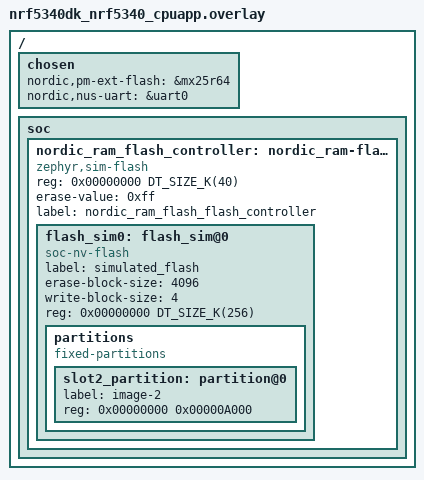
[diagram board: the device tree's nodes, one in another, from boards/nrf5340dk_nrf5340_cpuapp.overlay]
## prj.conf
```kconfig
#
# Copyright (c) 2018 Nordic Semiconductor
#
# SPDX-License-Identifier: LicenseRef-Nordic-5-Clause
#

# Enable the UART driver
CONFIG_UART_ASYNC_API=y
CONFIG_NRFX_UARTE0=y
CONFIG_SERIAL=y

CONFIG_GPIO=y

# Make sure printk is printing to the UART console
CONFIG_CONSOLE=y
CONFIG_UART_CONSOLE=y

CONFIG_HEAP_MEM_POOL_SIZE=2048

CONFIG_BT=y
CONFIG_BT_PERIPHERAL=y
CONFIG_BT_DEVICE_NAME="Pigrun_UART_Service"
CONFIG_BT_DEVICE_APPEARANCE=833
CONFIG_BT_MAX_CONN=1
CONFIG_BT_MAX_PAIRED=1

# Enable the NUS service
CONFIG_BT_NUS=y

# Enable bonding
CONFIG_BT_SETTINGS=y
CONFIG_FLASH=y
CONFIG_FLASH_PAGE_LAYOUT=y
CONFIG_FLASH_MAP=y
CONFIG_NVS=y
CONFIG_SETTINGS=y

# Enable DK LED and Buttons library
CONFIG_DK_LIBRARY=y

# This example requires more workqueue stack
CONFIG_SYSTEM_WORKQUEUE_STACK_SIZE=2048

# Config logger
CONFIG_LOG=y
CONFIG_USE_SEGGER_RTT=y
CONFIG_LOG_BACKEND_RTT=y
CONFIG_LOG_BACKEND_UART=n

CONFIG_ASSERT=y
```

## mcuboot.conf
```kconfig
CONFIG_MCUBOOT_UTIL_LOG_LEVEL_DBG=y
CONFIG_MCUBOOT_LOG_LEVEL_DBG=y
CONFIG_LOG_BACKEND_UART=y
CONFIG_MCUBOOT_SERIAL=y
CONFIG_BOOT_SERIAL_UART=y
CONFIG_BOOT_SERIAL_DETECT_PORT="GPIO_0" # or GPIO_1 if your pin is on that port
CONFIG_BOOT_SERIAL_DETECT_PIN=23
CONFIG_BOOT_SERIAL_DETECT_PIN_VAL=0
CONFIG_UART_CONSOLE=n
CONFIG_LOG=y
CONFIG_MCUBOOT_INDICATION_LED=y
```

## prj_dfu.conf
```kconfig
# Happirin add for DFU develop
CONFIG_CONSOLE=y
CONFIG_SERIAL=y
CONFIG_BOOTLOADER_MCUBOOT=y
CONFIG_MCUMGR=y
CONFIG_PCD_APP=y

# Increase system workqueue stack size to prevent stack overflows while handling
# SMP requests.
CONFIG_SYSTEM_WORKQUEUE_STACK_SIZE=4096
CONFIG_MAIN_STACK_SIZE=4096
CONFIG_THREAD_NAME=y
# BT dfu
# CONFIG_MCUMGR_LOG_LEVEL_DBG=y
# CONFIG_MCUMGR_CMD_OS_MGMT=y
# CONFIG_MCUMGR_CMD_IMG_MGMT=y
CONFIG_MCUMGR_SMP_BT=y
CONFIG_MCUMGR_SMP_BT_AUTHEN=n
# CONFIG_PCD_LOG_LEVEL_DBG=y
CONFIG_BT_L2CAP_TX_MTU=498
CONFIG_BT_BUF_ACL_TX_SIZE=251
CONFIG_BT_BUF_ACL_RX_SIZE=502
CONFIG_MCUMGR_BUF_COUNT=6

# Serial DFU
CONFIG_MCUMGR_SMP_UART=y
CONFIG_UART_MCUMGR_RX_BUF_SIZE=512
CONFIG_MCUMGR_BUF_SIZE=512
## Required by the `taskstat` command.
CONFIG_THREAD_MONITOR=y
CONFIG_STATS=y
CONFIG_STATS_NAMES=y
CONFIG_MCUMGR_CMD_OS_MGMT=y
CONFIG_MCUMGR_CMD_STAT_MGMT=y
CONFIG_MCUMGR_CMD_IMG_MGMT=y
```

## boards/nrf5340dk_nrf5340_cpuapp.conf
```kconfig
#
# Copyright (c) 2022 Nordic Semiconductor ASA
#
# SPDX-License-Identifier: LicenseRef-Nordic-5-Clause
#
################################################################################
# Application overlay - Nrf5340: DFU

CONFIG_MCUMGR=y
CONFIG_MCUMGR_SMP_BT=y
CONFIG_MCUMGR_SMP_BT_AUTHEN=n
CONFIG_MCUMGR_SMP_BT_CONN_PARAM_CONTROL=y

CONFIG_MCUMGR_CMD_IMG_MGMT=y
CONFIG_MCUMGR_CMD_OS_MGMT=y

# Enable custom SMP request to erase settings partition.
CONFIG_MCUMGR_GRP_ZEPHYR_BASIC=y
CONFIG_MCUMGR_GRP_BASIC_CMD_STORAGE_ERASE=y

# Increase system workqueue stack size to prevent stack overflows while handling
# SMP requests.
CONFIG_SYSTEM_WORKQUEUE_STACK_SIZE=2800

CONFIG_BT_L2CAP_TX_MTU=498
CONFIG_BT_BUF_ACL_TX_SIZE=251
CONFIG_BT_BUF_ACL_RX_SIZE=502

# Use connection parameters that ensure quick data transfer
CONFIG_BT_PERIPHERAL_PREF_MIN_INT=6
CONFIG_BT_PERIPHERAL_PREF_MAX_INT=6
CONFIG_BT_PERIPHERAL_PREF_LATENCY=99
CONFIG_BT_PERIPHERAL_PREF_TIMEOUT=400

################################################################################
# Bootloader configuration

CONFIG_BOOTLOADER_MCUBOOT=y
CONFIG_MCUBOOT_IMAGE_VERSION="1.0.0+0"
CONFIG_UPDATEABLE_IMAGE_NUMBER=2

CONFIG_IMG_MANAGER=y
CONFIG_MCUBOOT_IMG_MANAGER=y
CONFIG_IMG_ERASE_PROGRESSIVELY=y

################################################################################
# External flash configuration

CONFIG_NORDIC_QSPI_NOR=y
CONFIG_NORDIC_QSPI_NOR_FLASH_LAYOUT_PAGE_SIZE=4096
CONFIG_NORDIC_QSPI_NOR_STACK_WRITE_BUFFER_SIZE=16

# FLASH nop device is enabled to prevent bus faults when mcumgr tries to access
# simulated partition with network core image data.
CONFIG_FLASH_NOP_DEVICE=y
```

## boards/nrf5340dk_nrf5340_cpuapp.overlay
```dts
/*
 * Copyright (c) 2022 Nordic Semiconductor ASA
 *
 * SPDX-License-Identifier: LicenseRef-Nordic-5-Clause
 */

/ {
	chosen {
		nordic,pm-ext-flash = &mx25r64;
	};
};

/ {
	chosen {
		nordic,nus-uart = &uart0;
	};
};

/*
 * This section is used to enable a partition which is used through the flash API
 * but which is in reality stored in RAM. This is done to load data from
 * external flash to the network core. Since the network core cannot access
 * the external flash directly, the data is buffered in RAM before being
 * copied by the network core to the network core flash.
 *
 * The partition must be enabled by the application configuration to prevent
 * bus faults when mcumgr tries to access simulated partition with network core
 * image data.
 */

/ {
	soc {
		/* Add a flash controller which has the compatible
		 * 'zephyr,sim-flash'. This will ensure that the flash
		 * simulator can use it. None of the other properties in this
		 * node is used for anything.
		 */
		nordic_ram_flash_controller: nordic_ram-flash-controller@0 {
			compatible = "zephyr,sim-flash";
			reg = <0x00000000 DT_SIZE_K(40)>;
			#address-cells = <1>;
			#size-cells = <1>;
			erase-value = <0xff>;
			label = "nordic_ram_flash_flash_controller";

			/* This node label must match that used in the flash
			 * simulator.
			 */
			flash_sim0: flash_sim@0 {
				status = "okay";
				compatible = "soc-nv-flash";
				label = "simulated_flash";
				erase-block-size = <4096>;
				write-block-size = <4>;
				reg = <0x00000000 DT_SIZE_K(256)>;

				partitions {
					compatible = "fixed-partitions";
					#address-cells = <1>;
					#size-cells = <1>;

					/* This partition must be defined for
					 * MCUboot to find the partition ID
					 * of the primary slot for image 1,
					 * which is stored in this partition.
					 */
					slot2_partition: partition@0 {
						label = "image-2";
						reg = <0x00000000 0x00000A000>;
					};
				};
			};
		};
	};

};
```

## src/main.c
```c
/*
 * Copyright (c) 2018 Nordic Semiconductor ASA
 *
 * SPDX-License-Identifier: LicenseRef-Nordic-5-Clause
 */

/** @file
 *  @brief Nordic UART Bridge Service (NUS) sample
 */
#include "uart_async_adapter.h"

#include <zephyr/types.h>
#include <zephyr.h>
#include <drivers/uart.h>
#include <usb/usb_device.h>

#include <device.h>
#include <devicetree.h>
#include <soc.h>

#include <bluetooth/bluetooth.h>
#include <bluetooth/uuid.h>
#include <bluetooth/gatt.h>
#include <bluetooth/hci.h>

#include <bluetooth/services/nus.h>

#include <dk_buttons_and_leds.h>

#include <settings/settings.h>

#include <stdio.h>

#include <logging/log.h>

#define LOG_MODULE_NAME peripheral_uart
LOG_MODULE_REGISTER(LOG_MODULE_NAME);

#define STACKSIZE CONFIG_BT_NUS_THREAD_STACK_SIZE
#define PRIORITY 7

#define DEVICE_NAME CONFIG_BT_DEVICE_NAME
#define DEVICE_NAME_LEN	(sizeof(DEVICE_NAME) - 1)

#define RUN_STATUS_LED DK_LED1
#define RUN_LED_BLINK_INTERVAL 1000

#define CON_STATUS_LED DK_LED2

#define KEY_PASSKEY_ACCEPT DK_BTN1_MSK
#define KEY_PASSKEY_REJECT DK_BTN2_MSK

#define UART_BUF_SIZE CONFIG_BT_NUS_UART_BUFFER_SIZE
#define UART_WAIT_FOR_BUF_DELAY K_MSEC(50)
#define UART_WAIT_FOR_RX CONFIG_BT_NUS_UART_RX_WAIT_TIME

static K_SEM_DEFINE(ble_init_ok, 0, 1);

static struct bt_conn *current_conn;
static struct bt_conn *auth_conn;

static const struct device *uart = DEVICE_DT_GET(DT_CHOSEN(nordic_nus_uart));
static struct k_work_delayable uart_work;

struct uart_data_t {
	void *fifo_reserved;
	uint8_t data[UART_BUF_SIZE];
	uint16_t len;
};

static K_FIFO_DEFINE(fifo_uart_tx_data);
static K_FIFO_DEFINE(fifo_uart_rx_data);

static const struct bt_data ad[] = {
	BT_DATA_BYTES(BT_DATA_FLAGS, (BT_LE_AD_GENERAL | BT_LE_AD_NO_BREDR)),
	BT_DATA(BT_DATA_NAME_COMPLETE, DEVICE_NAME, DEVICE_NAME_LEN),
};

static const struct bt_data sd[] = {
	BT_DATA_BYTES(BT_DATA_UUID128_ALL, BT_UUID_NUS_VAL),
};

#if CONFIG_BT_NUS_UART_ASYNC_ADAPTER
UART_ASYNC_ADAPTER_INST_DEFINE(async_adapter);
#else
static const struct device *const async_adapter;
#endif

static void uart_cb(const struct device *dev, struct uart_event *evt, void *user_data)
{
	ARG_UNUSED(dev);

	static size_t aborted_len;
	struct uart_data_t *buf;
	static uint8_t *aborted_buf;
	static bool disable_req;

	switch (evt->type) {
	case UART_TX_DONE:
		LOG_DBG("UART_TX_DONE");
		if ((evt->data.tx.len == 0) ||
		    (!evt->data.tx.buf)) {
			return;
		}

		if (aborted_buf) {
			buf = CONTAINER_OF(aborted_buf, struct uart_data_t,
					   data);
			aborted_buf = NULL;
			aborted_len = 0;
		} else {
			buf = CONTAINER_OF(evt->data.tx.buf, struct uart_data_t,
					   data);
		}

		k_free(buf);

		buf = k_fifo_get(&fifo_uart_tx_data, K_NO_WAIT);
		if (!buf) {
			return;
		}

		if (uart_tx(uart, buf->data, buf->len, SYS_FOREVER_MS)) {
			LOG_WRN("Failed to send data over UART");
		}

		break;

	case UART_RX_RDY:
		LOG_DBG("UART_RX_RDY");
		buf = CONTAINER_OF(evt->data.rx.buf, struct uart_data_t, data);
		buf->len += evt->data.rx.len;

		if (disable_req) {
			return;
		}

		if ((evt->data.rx.buf[buf->len - 1] == '\n') ||
		    (evt->data.rx.buf[buf->len - 1] == '\r')) {
			disable_req = true;
			uart_rx_disable(uart);
		}

		break;

	case UART_RX_DISABLED:
		LOG_DBG("UART_RX_DISABLED");
		disable_req = false;

		buf = k_malloc(sizeof(*buf));
		if (buf) {
			buf->len = 0;
		} else {
			LOG_WRN("Not able to allocate UART receive buffer");
			k_work_reschedule(&uart_work, UART_WAIT_FOR_BUF_DELAY);
			return;
		}

		uart_rx_enable(uart, buf->data, sizeof(buf->data),
			       UART_WAIT_FOR_RX);

		break;

	case UART_RX_BUF_REQUEST:
		LOG_DBG("UART_RX_BUF_REQUEST");
		buf = k_malloc(sizeof(*buf));
		if (buf) {
			buf->len = 0;
			uart_rx_buf_rsp(uart, buf->data, sizeof(buf->data));
		} else {
			LOG_WRN("Not able to allocate UART receive buffer");
		}

		break;

	case UART_RX_BUF_RELEASED:
		LOG_DBG("UART_RX_BUF_RELEASED");
		buf = CONTAINER_OF(evt->data.rx_buf.buf, struct uart_data_t,
				   data);

		if (buf->len > 0) {
			k_fifo_put(&fifo_uart_rx_data, buf);
		} else {
			k_free(buf);
		}

		break;

	case UART_TX_ABORTED:
		LOG_DBG("UART_TX_ABORTED");
		if (!aborted_buf) {
			aborted_buf = (uint8_t *)evt->data.tx.buf;
		}

		aborted_len += evt->data.tx.len;
		buf = CONTAINER_OF(aborted_buf, struct uart_data_t,
				   data);

		uart_tx(uart, &buf->data[aborted_len],
			buf->len - aborted_len, SYS_FOREVER_MS);

		break;

	default:
		break;
	}
}

static void uart_work_handler(struct k_work *item)
{
	struct uart_data_t *buf;

	buf = k_malloc(sizeof(*buf));
	if (buf) {
		buf->len = 0;
	} else {
		LOG_WRN("Not able to allocate UART receive buffer");
		k_work_reschedule(&uart_work, UART_WAIT_FOR_BUF_DELAY);
		return;
	}

	uart_rx_enable(uart, buf->data, sizeof(buf->data), UART_WAIT_FOR_RX);
}

static bool uart_test_async_api(const struct device *dev)
{
	const struct uart_driver_api *api =
			(const struct uart_driver_api *)dev->api;

	return (api->callback_set != NULL);
}

static int uart_init(void)
{
	int err;
	int pos;
	struct uart_data_t *rx;
	struct uart_data_t *tx;

	if (!device_is_ready(uart)) {
		return -ENODEV;
	}

	if (IS_ENABLED(CONFIG_USB_DEVICE_STACK)) {
		err = usb_enable(NULL);
		if (err) {
			LOG_ERR("Failed to enable USB");
			return err;
		}
	}

	rx = k_malloc(sizeof(*rx));
	if (rx) {
		rx->len = 0;
	} else {
		return -ENOMEM;
	}

	k_work_init_delayable(&uart_work, uart_work_handler);


	if (IS_ENABLED(CONFIG_BT_NUS_UART_ASYNC_ADAPTER) && !uart_test_async_api(uart)) {
		/* Implement API adapter */
		uart_async_adapter_init(async_adapter, uart);
		uart = async_adapter;
	}

	err = uart_callback_set(uart, uart_cb, NULL);
	if (err) {
		LOG_ERR("Cannot initialize UART callback");
		return err;
	}

	if (IS_ENABLED(CONFIG_UART_LINE_CTRL)) {
		LOG_INF("Wait for DTR");
		while (true) {
			uint32_t dtr = 0;

			uart_line_ctrl_get(uart, UART_LINE_CTRL_DTR, &dtr);
			if (dtr) {
				break;
			}
			/* Give CPU resources to low priority threads. */
			k_sleep(K_MSEC(100));
		}
		LOG_INF("DTR set");
		err = uart_line_ctrl_set(uart, UART_LINE_CTRL_DCD, 1);
		if (err) {
			LOG_WRN("Failed to set DCD, ret code %d", err);
		}
		err = uart_line_ctrl_set(uart, UART_LINE_CTRL_DSR, 1);
		if (err) {
			LOG_WRN("Failed to set DSR, ret code %d", err);
		}
	}

	tx = k_malloc(sizeof(*tx));

	if (tx) {
		pos = snprintf(tx->data, sizeof(tx->data),
			       "Starting Nordic UART service example\r\n");
		#if IS_ENABLED(CONFIG_BOOTLOADER_MCUBOOT)
		LOG_INF("%s", CONFIG_MCUBOOT_IMAGE_VERSION);
		#endif
		if ((pos < 0) || (pos >= sizeof(tx->data))) {
			k_free(tx);
			LOG_ERR("snprintf returned %d", pos);
			return -ENOMEM;
		}

		tx->len = pos;
	} else {
		return -ENOMEM;
	}

	err = uart_tx(uart, tx->data, tx->len, SYS_FOREVER_MS);
	if (err) {
		LOG_ERR("Cannot display welcome message (err: %d)", err);
		return err;
	}
	#if IS_ENABLED(CONFIG_BOOTLOADER_MCUBOOT)
		k_sleep(K_MSEC(1000));
		pos = snprintf(tx->data, sizeof(tx->data),
			       "%s \r\n", log_strdup(CONFIG_MCUBOOT_IMAGE_VERSION));
		tx->len = pos;
		err = uart_tx(uart, tx->data, tx->len, SYS_FOREVER_MS);

	#endif
	return uart_rx_enable(uart, rx->data, sizeof(rx->data), 50);
}

static void connected(struct bt_conn *conn, uint8_t err)
{
	char addr[BT_ADDR_LE_STR_LEN];

	if (err) {
		LOG_ERR("Connection failed (err %u)", err);
		return;
	}

	bt_addr_le_to_str(bt_conn_get_dst(conn), addr, sizeof(addr));
	LOG_INF("Connected %s", log_strdup(addr));

	current_conn = bt_conn_ref(conn);

	dk_set_led_on(CON_STATUS_LED);
}

static void disconnected(struct bt_conn *conn, uint8_t reason)
{
	char addr[BT_ADDR_LE_STR_LEN];

	bt_addr_le_to_str(bt_conn_get_dst(conn), addr, sizeof(addr));

	LOG_INF("Disconnected: %s (reason %u)", log_strdup(addr), reason);

	if (auth_conn) {
		bt_conn_unref(auth_conn);
		auth_conn = NULL;
	}

	if (current_conn) {
		bt_conn_unref(current_conn);
		current_conn = NULL;
		dk_set_led_off(CON_STATUS_LED);
	}
}

#ifdef CONFIG_BT_NUS_SECURITY_ENABLED
static void security_changed(struct bt_conn *conn, bt_security_t level,
			     enum bt_security_err err)
{
	char addr[BT_ADDR_LE_STR_LEN];

	bt_addr_le_to_str(bt_conn_get_dst(conn), addr, sizeof(addr));

	if (!err) {
		LOG_INF("Security changed: %s level %u", log_strdup(addr),
			level);
	} else {
		LOG_WRN("Security failed: %s level %u err %d", log_strdup(addr),
			level, err);
	}
}
#endif

BT_CONN_CB_DEFINE(conn_callbacks) = {
	.connected    = connected,
	.disconnected = disconnected,
#ifdef CONFIG_BT_NUS_SECURITY_ENABLED
	.security_changed = security_changed,
#endif
};

#if defined(CONFIG_BT_NUS_SECURITY_ENABLED)
static void auth_passkey_display(struct bt_conn *conn, unsigned int passkey)
{
	char addr[BT_ADDR_LE_STR_LEN];

	bt_addr_le_to_str(bt_conn_get_dst(conn), addr, sizeof(addr));

	LOG_INF("Passkey for %s: %06u", log_strdup(addr), passkey);
}

static void auth_passkey_confirm(struct bt_conn *conn, unsigned int passkey)
{
	char addr[BT_ADDR_LE_STR_LEN];

	auth_conn = bt_conn_ref(conn);

	bt_addr_le_to_str(bt_conn_get_dst(conn), addr, sizeof(addr));

	LOG_INF("Passkey for %s: %06u", log_strdup(addr), passkey);
	LOG_INF("Press Button 1 to confirm, Button 2 to reject.");
}


static void auth_cancel(struct bt_conn *conn)
{
	char addr[BT_ADDR_LE_STR_LEN];

	bt_addr_le_to_str(bt_conn_get_dst(conn), addr, sizeof(addr));

	LOG_INF("Pairing cancelled: %s", log_strdup(addr));
}


static void pairing_complete(struct bt_conn *conn, bool bonded)
{
	char addr[BT_ADDR_LE_STR_LEN];

	bt_addr_le_to_str(bt_conn_get_dst(conn), addr, sizeof(addr));

	LOG_INF("Pairing completed: %s, bonded: %d", log_strdup(addr),
		bonded);
}


static void pairing_failed(struct bt_conn *conn, enum bt_security_err reason)
{
	char addr[BT_ADDR_LE_STR_LEN];

	bt_addr_le_to_str(bt_conn_get_dst(conn), addr, sizeof(addr));

	LOG_INF("Pairing failed conn: %s, reason %d", log_strdup(addr),
		reason);
}


static struct bt_conn_auth_cb conn_auth_callbacks = {
	.passkey_display = auth_passkey_display,
	.passkey_confirm = auth_passkey_confirm,
	.cancel = auth_cancel,
	.pairing_complete = pairing_complete,
	.pairing_failed = pairing_failed
};
#else
static struct bt_conn_auth_cb conn_auth_callbacks;
#endif

static void bt_receive_cb(struct bt_conn *conn, const uint8_t *const data,
			  uint16_t len)
{
	int err;
	char addr[BT_ADDR_LE_STR_LEN] = {0};

	bt_addr_le_to_str(bt_conn_get_dst(conn), addr, ARRAY_SIZE(addr));

	LOG_INF("Received data from: %s", log_strdup(addr));

	for (uint16_t pos = 0; pos != len;) {
		struct uart_data_t *tx = k_malloc(sizeof(*tx));

		if (!tx) {
			LOG_WRN("Not able to allocate UART send data buffer");
			return;
		}

		/* Keep the last byte of TX buffer for potential LF char. */
		size_t tx_data_size = sizeof(tx->data) - 1;

		if ((len - pos) > tx_data_size) {
			tx->len = tx_data_size;
		} else {
			tx->len = (len - pos);
		}

		memcpy(tx->data, &data[pos], tx->len);

		pos += tx->len;

		/* Append the LF character when the CR character triggered
		 * transmission from the peer.
		 */
		if ((pos == len) && (data[len - 1] == '\r')) {
			tx->data[tx->len] = '\n';
			tx->len++;
		}

		err = uart_tx(uart, tx->data, tx->len, SYS_FOREVER_MS);
		if (err) {
			k_fifo_put(&fifo_uart_tx_data, tx);
		}
	}
}

static struct bt_nus_cb nus_cb = {
	.received = bt_receive_cb,
};

void error(void)
{
	dk_set_leds_state(DK_ALL_LEDS_MSK, DK_NO_LEDS_MSK);

	while (true) {
		/* Spin for ever */
		k_sleep(K_MSEC(1000));
	}
}

#ifdef CONFIG_BT_NUS_SECURITY_ENABLED
static void num_comp_reply(bool accept)
{
	if (accept) {
		bt_conn_auth_passkey_confirm(auth_conn);
		LOG_INF("Numeric Match, conn %p", (void *)auth_conn);
	} else {
		bt_conn_auth_cancel(auth_conn);
		LOG_INF("Numeric Reject, conn %p", (void *)auth_conn);
	}

	bt_conn_unref(auth_conn);
	auth_conn = NULL;
}

void button_changed(uint32_t button_state, uint32_t has_changed)
{
	uint32_t buttons = button_state & has_changed;

	if (auth_conn) {
		if (buttons & KEY_PASSKEY_ACCEPT) {
			num_comp_reply(true);
		}

		if (buttons & KEY_PASSKEY_REJECT) {
			num_comp_reply(false);
		}
	}
}
#endif /* CONFIG_BT_NUS_SECURITY_ENABLED */

static void configure_gpio(void)
{
	int err;

#ifdef CONFIG_BT_NUS_SECURITY_ENABLED
	err = dk_buttons_init(button_changed);
	if (err) {
		LOG_ERR("Cannot init buttons (err: %d)", err);
	}
#endif /* CONFIG_BT_NUS_SECURITY_ENABLED */

	err = dk_leds_init();
	if (err) {
		LOG_ERR("Cannot init LEDs (err: %d)", err);
	}
}

void main(void)
{
	int blink_status = 0;
	int err = 0;

	configure_gpio();

	err = uart_init();
	if (err) {
		error();
	}

	if (IS_ENABLED(CONFIG_BT_NUS_SECURITY_ENABLED)) {
		bt_conn_auth_cb_register(&conn_auth_callbacks);
	}

	err = bt_enable(NULL);
	if (err) {
		error();
	}

	LOG_INF("Bluetooth initialized");

	k_sem_give(&ble_init_ok);

	if (IS_ENABLED(CONFIG_SETTINGS)) {
		settings_load();
	}

	err = bt_nus_init(&nus_cb);
	if (err) {
		LOG_ERR("Failed to initialize UART service (err: %d)", err);
		return;
	}

	err = bt_le_adv_start(BT_LE_ADV_CONN, ad, ARRAY_SIZE(ad), sd,
			      ARRAY_SIZE(sd));
	if (err) {
		LOG_ERR("Advertising failed to start (err %d)", err);
		return;
	}
	#if IS_ENABLED(CONFIG_MCUMGR)
		img_mgmt_register_group();
		os_mgmt_register_group();
		smp_bt_register();
	#endif
	for (;;) {
		dk_set_led(RUN_STATUS_LED, (++blink_status) % 2);
		k_sleep(K_MSEC(RUN_LED_BLINK_INTERVAL));
	}
}

void ble_write_thread(void)
{
	/* Don't go any further until BLE is initialized */
	k_sem_take(&ble_init_ok, K_FOREVER);

	for (;;) {
		/* Wait indefinitely for data to be sent over bluetooth */
		struct uart_data_t *buf = k_fifo_get(&fifo_uart_rx_data,
						     K_FOREVER);

		if (bt_nus_send(NULL, buf->data, buf->len)) {
			LOG_WRN("Failed to send data over BLE connection");
		}

		k_free(buf);
	}
}

K_THREAD_DEFINE(ble_write_thread_id, STACKSIZE, ble_write_thread, NULL, NULL,
		NULL, PRIORITY, 0, 0);
```
